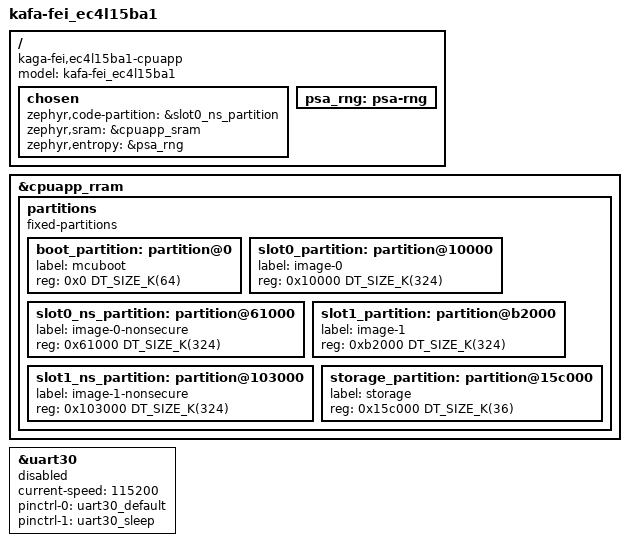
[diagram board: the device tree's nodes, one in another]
/*
 * Copyright (c) 2024 Nordic Semiconductor ASA
 * Copyright (c) 2025 KAGA FEI Co., Ltd.
 *
 * SPDX-License-Identifier: Apache-2.0
 */

/dts-v1/;

#define USE_NON_SECURE_ADDRESS_MAP 1

#include <nordic/nrf54l15_cpuapp.dtsi>
#include "ec4l15ba1-pinctrl.dtsi"

/ {
	model = "kafa-fei_ec4l15ba1";
	compatible = "kaga-fei,ec4l15ba1-cpuapp";

	chosen {

		zephyr,code-partition = &slot0_ns_partition;
		zephyr,sram = &cpuapp_sram;
		zephyr,entropy = &psa_rng;
	};

	/delete-node/ rng;

	psa_rng: psa-rng {
		status = "okay";
	};
};

&cpuapp_rram {
	partitions {
		compatible = "fixed-partitions";
		#address-cells = <1>;
		#size-cells = <1>;
		boot_partition: partition@0 {
			label = "mcuboot";
			reg = <0x0 DT_SIZE_K(64)>;
		};
		slot0_partition: partition@10000 {
			label = "image-0";
			reg = <0x10000 DT_SIZE_K(324)>;
		};
		slot0_ns_partition: partition@61000 {
			label = "image-0-nonsecure";
			reg = <0x61000 DT_SIZE_K(324)>;
		};
		slot1_partition: partition@b2000 {
			label = "image-1";
			reg = <0xb2000 DT_SIZE_K(324)>;
		};
		slot1_ns_partition: partition@103000 {
			label = "image-1-nonsecure";
			reg = <0x103000 DT_SIZE_K(324)>;
		};
		/* 32k from 0x154000 to 0x15bfff reserved for TF-M partitions */
		storage_partition: partition@15c000 {
			label = "storage";
			reg = <0x15c000 DT_SIZE_K(36)>;
		};
	};
};

&uart30 {
	/* Disable so that TF-M can use this UART */
	status = "disabled";

	current-speed = <115200>;
	pinctrl-0 = <&uart30_default>;
	pinctrl-1 = <&uart30_sleep>;
	pinctrl-names = "default", "sleep";
};
